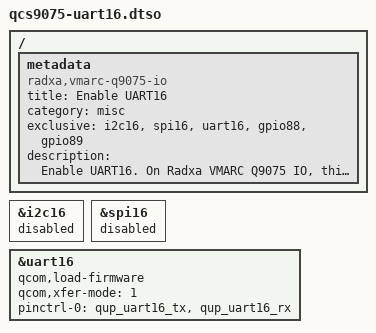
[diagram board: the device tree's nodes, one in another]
// SPDX-License-Identifier: BSD-3-Clause
/*
 * Copyright (c) 2026 Radxa Computer (Shenzhen) Co., Ltd.
 */

/dts-v1/;
/plugin/;

/ {
    metadata {
        title = "Enable UART16";
        compatible = "radxa,vmarc-q9075-io";
        category = "misc";
        exclusive = "i2c16", "spi16", "uart16", "gpio88", "gpio89";
        description = "Enable UART16.
On Radxa VMARC Q9075 IO, this pin 23(tx) & pin 24(rx).";
    };
};

&i2c16 {
    status = "disabled";
};

&spi16 {
	status = "disabled";
};

&uart16 {
	qcom,load-firmware;
	qcom,xfer-mode = <1>;
	status = "okay";
	pinctrl-0 = <&qup_uart16_tx>, <&qup_uart16_rx>;
	pinctrl-names = "default";
};
